# K32W061 register map
Vendor: nxp.com; File version: 1.0
CPU: CM4 r0p1, little endian, MPU, no FPU, VTOR, 3 interrupt priority bits
Registers are 32-bit, read-write, reset 0x0 unless marked. A register's access mark holds for its fields unless they carry their own. Offsets are from the block's base; [hi:lo] are bit positions; {n}, {i} and the like mark numbered series.

## PMC — This is the description of component pmc. It is the Power Management Unit Controller. More details will follow.
Base 0x40012000
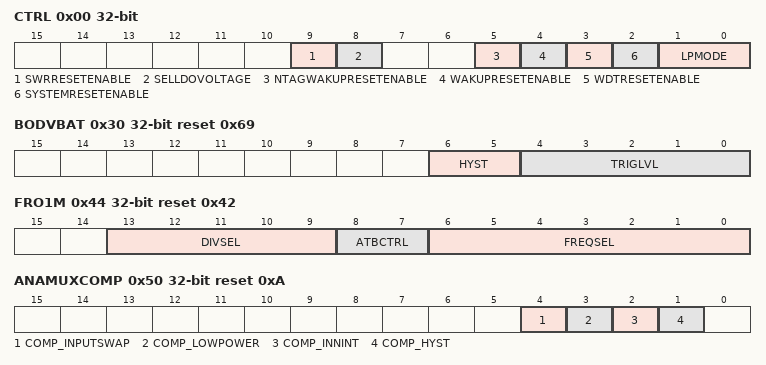
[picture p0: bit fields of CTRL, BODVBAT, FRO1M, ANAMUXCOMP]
0x00 CTRL — Power Management Control [Reset by POR, RSTN, WDT ]
  [9] SWRRESETENABLE — Software reset enable. If set enables the software reset to affect the system.
  [8] SELLDOVOLTAGE — 0 = all LDOs current output levels are determined by their associated VADJ bitfield. 1 = all LDOs current output levels are determined by their associated VADJ_2 bitfield.
  [5] NTAGWAKUPRESETENABLE — Wake-up NTAG reset enable. When set, the device can wake from deep power down by edge on NTAG FD signal, even if I/O power domain is off (see WAKUPRESETENABLE). Note that if I/O power domain is ON, wake-up by NTAG FD is enabled by default thus content of this bit does not care. Do not set unless entering Deep Power Down.
  [4] WAKUPRESETENABLE — Wake-up I/Os reset enable. When set, the I/O power domain is not shutoff in deep powerdown mode.
  [3] WDTRESETENABLE — Watchdog Timer reset enable. If set allow a watchdog timer reset event to affect the system.
  [2] SYSTEMRESETENABLE — ARM system reset request enable. If set enables the ARM system reset to affect the system.
  [1:0] LPMODE — Power Mode Control. 00: Active; 01: Deep Sleep; 10: Power Down; 11: Deep Power Down.
0x04 DCDC0 reset 0x4B67D — DCDC control register (1st). This reigster is controlled by the boot code and the Low power API software. [Reset by all reset sources, except ARM SystemReset]
0x08 DCDC1 reset 0x3C0647C — DCDC control register (2nd). This reigster is controlled by the boot code and the Low power API software. [Reset by all reset sources, except ARM SystemReset]
0x0C BIAS reset 0x20F48 — Bias current source control register. This reigster is controlled by the boot code and the Low power API software. [Reset by POR, RSTN, WDT ]
0x10 LDOPMU reset 0x3846E0B8 — PMU & Always On domains LDO control. This reigster is controlled by the boot code and the Low power API software. [Reset by all reset sources, except ARM SystemReset]
0x14 LDOMEM reset 0xC673318 — Memories LDO control register. This reigster is controlled by the boot code and the Low power API software. [Reset by all reset sources, except ARM SystemReset]
0x18 LDOCORE reset 0x5E2D — Digital Core LDO control register. This reigster is controlled by the boot code and the Low power API software. [Reset by all reset sources, except ARM SystemReset]
0x1C LDOFLASHNV reset 0x2CC05 — Flash LDO control register. This reigster is controlled by the boot code and the Low power API software. [Reset by all reset sources, except ARM SystemReset]
0x20 LDOFLASHCORE reset 0xBC6 — Flash Core LDO control register. This reigster is controlled by the boot code and the Low power API software. [Reset by all reset sources, except ARM SystemReset]
0x24 LDOADC reset 0xBC5 — General Purpose ADC LDO control register This reigster is controlled by the boot code and the Low power API software. [Reset by all reset sources, except ARM SystemReset]
0x30 BODVBAT reset 0x69 — VBAT Brown Out Dectector control register This reigster is controlled by the boot code and the Low power API software. [Reset by POR, RSTN, WDT ]
  [6:5] HYST — BOD Hysteresis control
  [4:0] TRIGLVL — BOD trigger level
0x40 FRO192M reset 0x780820 — High Speed FRO control register This reigster is controlled by the boot code and the Low power API software. [Reset by POR, RSTN, WDT ]
  [24:20] DIVSEL — Mode of operation (which clock to output). Each bit enables a clocks as shown. Enables are additive meaning that two or more clocks can be enabled together. xxxx1: 12MHz enabled; xxx1x: 32MHz enabled; xx1xx: 48MHz enabled; x1xxx: Not applicable; 1xxxx: Not applicable.
0x44 FRO1M reset 0x42 — 1 MHz Free Running Oscillator control register. [Reset by all reset sources, except ARM SystemReset]
  [13:9] DIVSEL — Divider selection bits.
  [8:7] ATBCTRL — Debug control bits to set the analog/digital test modes; only required for test purposes.
  [6:0] FREQSEL — Frequency trimming bits. This field is used to give accurate frequency for each device. The required setting is based upon calibration data sotred in flash during device test. This setting is applied by the clock driver function.
0x50 ANAMUXCOMP reset 0xA — Analog Comparator and Analog Mux control register. [Reset by all reset sources, except ARM SystemReset]
  [4] COMP_INPUTSWAP — Input swap is enabled when set. Comparator{ _p, _n} ports are connected to {ACM, ACP}. Otherwsie normal configuration occurs, {_p, _n} is connected to {ACP, ACM} .
  [3] COMP_LOWPOWER — Comparator Low power mode enabled when set.
  [2] COMP_INNINT — Voltage reference inn_int input is selected for _n comparator input when sel_inn_int = 1 . This setting also requires PMU_BIASING to be active. Also flash biasing and DCDC converter needs to be enabled. If this setting = '0' then _n input comes from device pins, based on COMP_INPUTSWAP setting.
  [1] COMP_HYST — Hysteris enabled in comparator when hyst = '1', no hysteresis when = '0'.
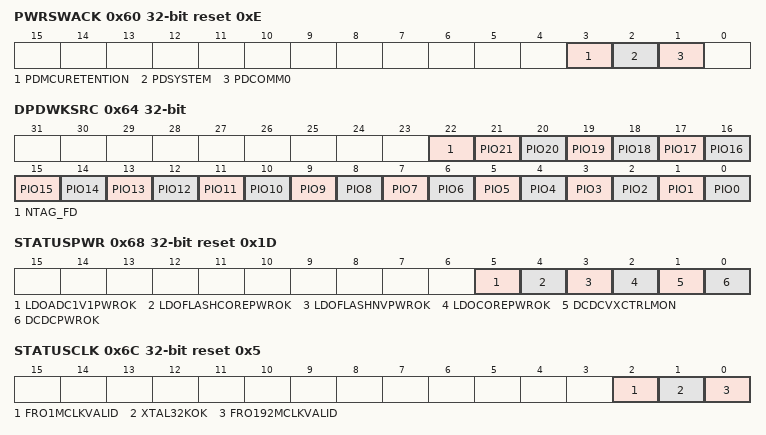
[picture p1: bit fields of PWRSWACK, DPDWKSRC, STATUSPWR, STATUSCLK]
0x60 PWRSWACK ro reset 0xE — Power Switch acknowledge. [Reset by all reset sources, except ARM SystemReset]
  [3] PDMCURETENTION — MCU Retention Power Domain power switch status.
  [2] PDSYSTEM — System Power Domain power switch status.
  [1] PDCOMM0 — Comm0 (USART0, I2C0, SPI0) Power Domain power switch status.
0x64 DPDWKSRC — Power Down and Deep Power Down wake-up source. [Reset by POR, RSTN, WDT ]
  [22] NTAG_FD — Enable / disable wakeup from Power down and Deep Power Down modes by NTAG_FD: 0: Disable; 1: Enable.
  [n] PIO{n} (n=0..21) — Enable / disable wakeup from Power down and Deep Power Down modes by GPIO{n}: 0: Disable; 1: Enable.
0x68 STATUSPWR ro reset 0x1D — Power OK and Ready signals from various analog modules (DCDC, LDO, ). [Reset by all reset sources, except ARM SystemReset]
  [5] LDOADC1V1PWROK — General Purpose ADC LDO power OK. Max switch on time is 8us.
  [4] LDOFLASHCOREPWROK — Flash Core LDO power OK Max switch on time should be considered as 10us.
  [3] LDOFLASHNVPWROK — Flash NV LDO power OK Max switch on time 20us.
  [2] LDOCOREPWROK — CORE LDO power OK. Max switch on time 2us.
  [1] DCDCVXCTRLMON — Picture of the DCDC output state.
  [0] DCDCPWROK — DCDC converter power OK
0x6C STATUSCLK ro reset 0x5 — FRO and XTAL status register. [Reset by all reset sources, except ARM SystemReset]
  [2] FRO1MCLKVALID — FRO 1 MHz CCO voltage detector output.
  [1] XTAL32KOK — XTAL oscillator 32KHz OK signal. When the XTAL is stable, then a transition from 1 to 0 will indicate a clock issue. Can not be used to identify a stable clock during XTAL start.
  [0] FRO192MCLKVALID — High Speed FRO (FRO 192 MHz) clock valid signal. The FRO192M clock generator also generates the FRO12M, FRO32M and FRO48M clock signals. These will also be valid when this flag is assertetd.
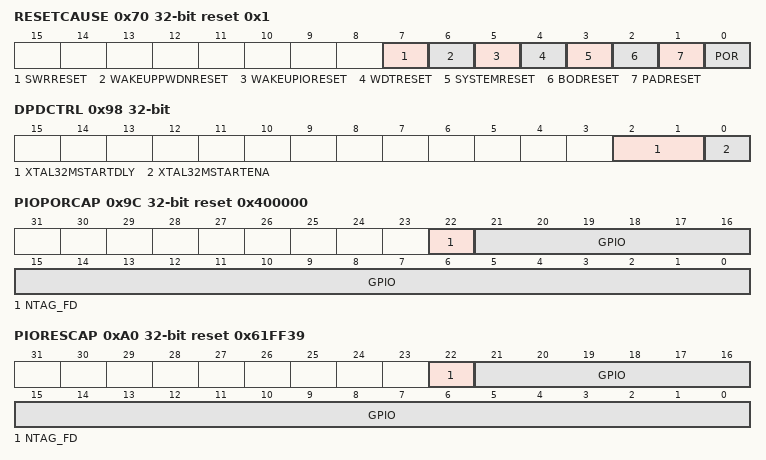
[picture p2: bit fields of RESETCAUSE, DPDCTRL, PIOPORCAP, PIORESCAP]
0x70 RESETCAUSE reset 0x1 — Reset Cause register. [Reset by POR]
  [7] SWRRESET — 1 : The last chip reset was caused by a Software. Write '1' to clear this bit.
  [6] WAKEUPPWDNRESET — 1 : The last CPU reset was caused by a Wake-up from Power down (many sources possible: timer, IO, ...). Write '1' to clear this bit. Check NVIC register if not waken-up by IO (NVIC_GetPendingIRQ).
  [5] WAKEUPIORESET — 1 : The last chip reset was caused by a Wake-up I/O (GPIO or internal NTAG FD INT). Write '1' to clear this bit.
  [4] WDTRESET — 1 : The last chip reset was caused by the Watchdog Timer. Write '1' to clear this bit.
  [3] SYSTEMRESET — 1 : The last chip reset was caused by a System Reset requested by the ARM CPU. Write '1' to clear this bit.
  [2] BODRESET — 1 : The last chip reset was caused by a Brown Out Detector. Write '1' to clear this bit.
  [1] PADRESET — 1 : The last chip reset was caused by a Pad Reset. Write '1' to clear this bit.
  [0] POR — 1 : The last chip reset was caused by a Power On Reset. Write '1' to clear this bit.
0x80 AOREG0 — General purpose always on domain data storage. [Reset by all reset sources, except ARM SystemReset]
  [31:0] DATA31_0 — General purpose always on domain data storage. Only writable 1 time after any chip reset. After the 1st write, any further writes are blocked. After any chip reset the write block is disabled until after next write. The chip reset includes POR, RSTIN, WDT reset, SW reset and WAKEUP IO reset.
0x84 AOREG1 — General purpose always on domain data storage. [Reset by POR, RSTN]
  [31:0] DATA31_0 — Reserved for use by NXP system software. General purpose always on domain data storage. Only reinitialized on Power On Reset and RSTIN Pin reset.
0x88 AOREG2 — General purpose always on domain data storage. [Reset by POR, RSTN]
  [31:0] DATA31_0 — General purpose always on domain data storage. Only reinitialized on Power On Reset and RSTIN Pin reset.
0x98 DPDCTRL — Configuration parameters for Power Down and Deep Power Down mode. [Reset by POR, RSTN, WDT ]
  [2:1] XTAL32MSTARTDLY — Delay between xtal ldo enable and release of reset to xtal 0:16us 1:32us 2:48us 3:64us. LSB reset value set by efuse (wake-up by I/O only). This delay is applied within PMC for Efuse controlled XTAL start and also BLE link layer for BLE controlled auto-start.
  [0] XTAL32MSTARTENA — Enable XTAL32MHz automatic start-up at power up & wake up from power down or deep power down. Reset value is set by eFuse content. This register field will overwrite option selected by eFuse content only if power-up or wake-up is NOT triggered by any kind of reset. Thus if power-up or wake-up is triggered by I/O or a timer. On the contrary, if power-up or wake-up is triggered by POR (typically during initial power up) or watchdog reset or SW reset or PAD RSTN then eFuse content will reset this register and will be applied. Take care that option selected here can by masked in power down by a register of SYSCON - XTAL32MCTRL - which is itself reset after each deep power down. Thus SYSCON/XTAL32MCTRL will not have any impact after a deep power down, only after a power down.
0x9C PIOPORCAP ro reset 0x400000 — The PIOPORCAP register captures the state of GPIO at power-on-reset or pin reset. Each bit represents the power-on reset state of one GPIO pin. [Reset by POR, RSTN]
  [22] NTAG_FD — Capture of NTAG_FD value at power-on-reset and pin reset.
  [21:0] GPIO — Capture of GPIO values at power-on-reset and pin reset.
0xA0 PIORESCAP ro reset 0x61FF39 — The PIORESCAP0 register captures the state of GPIO port 0 when a reset other than a power-on reset or pin reset occurs. Each bit represents the reset state of one GPIO pin. [Reset by WDT, BOD, WAKEUP IO, ARM System reset ]
  [22] NTAG_FD — Capture of NTAG_FD value.
  [21:0] GPIO — Capture of GPIO values.
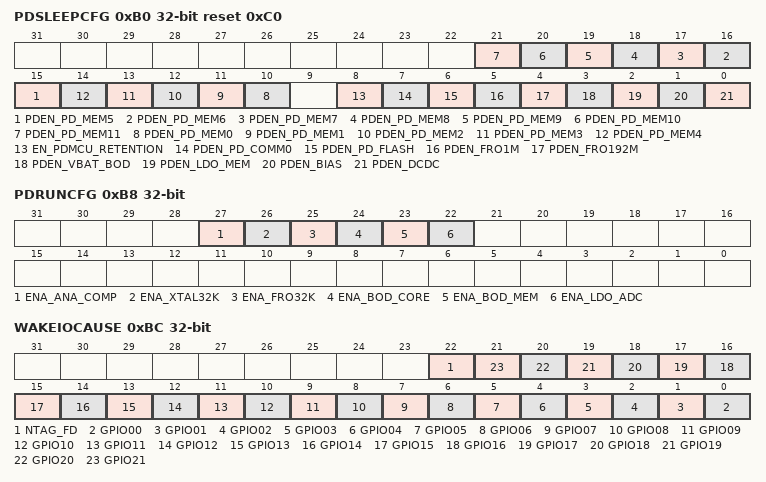
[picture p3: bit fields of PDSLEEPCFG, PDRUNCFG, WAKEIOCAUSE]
0xB0 PDSLEEPCFG reset 0xC0 — Controls the power to various modules in Low Power modes. [Reset by all reset sources, except ARM SystemReset]
  [n+10] PDEN_PD_MEM{n} (n=5..11) — Enable Power Down mode of SRAM {n} when entering in Powerdown mode. Automatically switched off in deep power down
  [n+10] PDEN_PD_MEM{n} (n=0..4) — Enable Power Down mode of SRAM {n} when entering in Powerdown mode. Automatically switched off in deep power down.
  [8] EN_PDMCU_RETENTION — Enable MCU Power Domain state retention when entering in 'Powerdown' mode for modem and radio cal values
  [7] PDEN_PD_COMM0 — Enable Comm0 power domain (USART0, I2C0, SPI0) Power Down mode when entering in Powerdown mode. In Deep power down it is disabled by hardware. In deep sleep it is always enabled.
  [6] PDEN_PD_FLASH — Enable Flash power domain Power Down mode (power shutoff) when entering in DeepSleep. In PowerDown modes this domain is automatically powered off.
  [5] PDEN_FRO1M — Controls FRO1M power in Deep Sleep, Power down and Deep Power down modes. This should be disabled before entering power down (unless needed for low power timers) or deep power down mode. 0: FRO1M is disabled; 1: FRO1M is enabled.
  [4] PDEN_FRO192M — Controls FRO192M power in Deep Sleep, Power down and Deep Power down modes. This should be disabled before entering power down or deep power down mode. 0: FRO192M is disabled; 1: FRO192M is enabled.
  [3] PDEN_VBAT_BOD — Controls VBAT BOD power in Power down and Deep Power down modes. 0: VBAT BOD is disabled in Power down and Deep Power down modes; 1: VBAT BOD is enabled in Power down and Deep Power down modes.
  [2] PDEN_LDO_MEM — Controls LDO memories power in Power down mode. Automatically switched off in deep power down 0: LDO is disabled in Power down mode; 1: LDO is enabled in Power down mode.
  [1] PDEN_BIAS — Controls Bias power in Power down and Deep Power down modes. 0: Bias is disabled in Power down and Deep Power down modes; 1: Bias is enabled in Power down and Deep Power down modes.
  [0] PDEN_DCDC — Controls DCDC power in Power down and Deep Power down modes. Automatically switched off in deep power down. 0: DCDC is disabled in Power down and Deep Power down modes; 1: DCDC is enabled in Power down and Deep Power down modes.
0xB8 PDRUNCFG — Controls the power to various analog blocks. [Reset by all reset sources, except ARM SystemReset]
  [27] ENA_ANA_COMP — Analog Comparator enabled.
  [26] ENA_XTAL32K — XTAL32K enabled.
  [25] ENA_FRO32K — FRO32K enabled.
  [24] ENA_BOD_CORE — BOD CORE enabled.
  [23] ENA_BOD_MEM — BOD MEM enabled.
  [22] ENA_LDO_ADC — LDO ADC enabled. See STATUSPWR.LDOADC1V1PWROK for when the power domain is ready.
0xBC WAKEIOCAUSE ro — Wake-up source from Power Down and Deep Power Down modes. Allow to identify the Wake-up source from Power-Down mode or Deep Power Down mode.[Reset by POR, RSTN, WDT ]
  [22] NTAG_FD — Wake up was triggered by NTAG FD
  [n] GPIO{n:02} (n=0..21) — Wake up was triggered by GPIO {n:02}
0xCC CTRLNORST — Extension of CTRL register, but never reset except by POR
  [2:0] FASTLDOENABLE — Fast LDO wake-up enable. 3 bits for the different wake-up sources: {generic async wake up event as selected by SLEEPCON/STARTER0&1, IO wake-up event, RSTN pad event}. If required, this field should only be managed by the Low power driver software.
